# apollo3p register map
Vendor: Ambiq Micro; Series: Apollo; File version: 1.0
CPU: CM4 r1p0, little endian, MPU, FPU, I-cache, D-cache, VTOR, ITCM, DTCM, 3 interrupt priority bits, 0 interrupts
Registers are 32-bit, read-write, reset 0x0 unless marked. A register's access mark holds for its fields unless they carry their own. Offsets are from the block's base; [hi:lo] are bit positions; lines under a group give offsets from that group; {n}, {i} and the like mark numbered series; 'fields as' and 'values as' point back to an identical list.

## GPIO (part 1 of 2) — General Purpose IO
Base 0x40010000
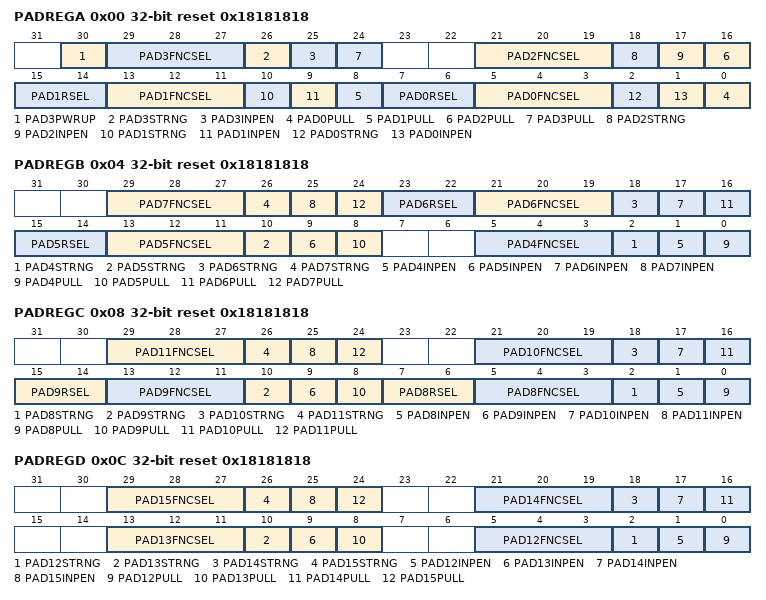
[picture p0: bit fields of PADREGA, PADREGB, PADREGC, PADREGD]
0x00 PADREGA reset 0x18181818 — This register controls the pad configuration controls for PAD3 through PAD0. Writes to this register must be unlocked by the PADKEY register.
  [30] PAD3PWRUP — Pad 3 VDD power switch enable
    0=DIS (Power switch disabled); 1=EN (Power switch enabled (switched to VDD))
  [29:27] PAD3FNCSEL — Pad 3 function select
    0=UA0RTS (Configure as the UART0 RTS output); 1=SLnCE (Configure as the IOSLAVE SPI nCE signal); 2=NCE3 (IOM/MSPI nCE group 3); 3=GPIO3 (Configure as GPIO3); 5=MSPI7 (MSPI data connection 7); 6=TRIG1 (Configure as the ADC Trigger 1 signal); 7=I2S_WCLK (Configure as the PDM I2S Word Clock input)
  [26] PAD3STRNG — Pad 3 drive strength.
    0=LOW (Low drive strength); 1=HIGH (High drive strength)
  [25] PAD3INPEN — Pad 3 input enable.
    0=DIS (Pad input disabled); 1=EN (Pad input enabled)
  [8n] PAD{n}PULL (n=0..3) — Pad {n} pullup enable
    0=DIS (Pullup disabled); 1=EN (Pullup enabled)
  [21:19] PAD2FNCSEL — Pad 2 function select
    0=UART1RX (Configure as the UART1 RX input.); 1=SLMISO (Configure as the IOSLAVE SPI MISO signal.); 2=UART0RX (Configure as the UART0 RX input.); 3=GPIO2 (Configure as GPIO2.); 5=MSPI6 (MSPI data connection 6.); 7=NCE2 (IOM/MSPI nCE group 2)
  [18] PAD2STRNG — Pad 2 drive strength
    0=LOW (Low drive strength); 1=HIGH (High drive strength)
  [17] PAD2INPEN — Pad 2 input enable
    0=DIS (Pad input disabled); 1=EN (Pad input enabled)
  [15:14] PAD1RSEL — Pad 1 pullup resistor selection.
    0=PULL1_5K (Pullup is ~1.5 KOhms); 1=PULL6K (Pullup is ~6 KOhms); 2=PULL12K (Pullup is ~12 KOhms); 3=PULL24K (Pullup is ~24 KOhms)
  [13:11] PAD1FNCSEL — Pad 1 function select
    0=SLSDAWIR3 (Configure as the IOSLAVE I2C SDA or SPI WIR3 signal); 1=SLMOSI (Configure as the IOSLAVE SPI MOSI signal); 2=UART0TX (Configure as the UART0 TX output signal); 3=GPIO1 (Configure as GPIO1); 5=MSPI5 (MSPI data connection 5); 7=NCE1 (IOM/MSPI nCE group 1)
  [10] PAD1STRNG — Pad 1 drive strength
    0=LOW (Low drive strength); 1=HIGH (High drive strength)
  [9] PAD1INPEN — Pad 1 input enable
    0=DIS (Pad input disabled); 1=EN (Pad input enabled)
  [7:6] PAD0RSEL — Pad 0 pullup resistor selection.
    values as PAD1RSEL
  [5:3] PAD0FNCSEL — Pad 0 function select
    0=SLSCL (Configure as the IOSLAVE I2C SCL signal); 1=SLSCK (Configure as the IOSLAVE SPI SCK signal); 2=CLKOUT (Configure as the CLKOUT signal); 3=GPIO0 (Configure as GPIO0); 5=MSPI4 (MSPI data connection 4); 7=NCE0 (IOM/MSPI nCE group 0)
  [2] PAD0STRNG — Pad 0 drive strength
    0=LOW (Low drive strength); 1=HIGH (High drive strength)
  [1] PAD0INPEN — Pad 0 input enable
    0=DIS (Pad input disabled); 1=EN (Pad input enabled)
0x04 PADREGB reset 0x18181818 — This register controls the pad configuration controls for PAD7 through PAD4. Writes to this register must be unlocked by the PADKEY register.
  [29:27] PAD7FNCSEL — Pad 7 function select
    0=NCE7 (IOM/MSPI nCE group 7); 1=M0MOSI (Configure as the IOMSTR0 SPI MOSI signal); 2=CLKOUT (Configure as the CLKOUT signal); 3=GPIO7 (Configure as GPIO7); 4=TRIG0 (Configure as the ADC Trigger 0 signal); 5=UART0TX (Configure as the UART0 TX output signal); 7=CT19 (CTIMER connection 19)
  [8n-30] PAD{n}STRNG (n=4..7) — Pad {n} drive strength
    0=LOW (Low drive strength); 1=HIGH (High drive strength)
  [8n-31] PAD{n}INPEN (n=4..7) — Pad {n} input enable
    0=DIS (Pad input disabled); 1=EN (Pad input enabled)
  [8n-32] PAD{n}PULL (n=4..7) — Pad {n} pullup enable
    0=DIS (Pullup disabled); 1=EN (Pullup enabled)
  [23:22] PAD6RSEL — Pad 6 pullup resistor selection.
    values as PADREGA.PAD1RSEL
  [21:19] PAD6FNCSEL — Pad 6 function select
    0=M0SDAWIR3 (Configure as the IOMSTR0 I2C SDA or SPI WIR3 signal); 1=M0MISO (Configure as the IOMSTR0 SPI MISO signal); 2=UA0CTS (Configure as the UART0 CTS input signal); 3=GPIO6 (Configure as GPIO6); 5=CT10 (CTIMER connection 10); 7=I2S_DAT (Configure as the PDM I2S Data output signal)
  [15:14] PAD5RSEL — Pad 5 pullup resistor selection.
    values as PADREGA.PAD1RSEL
  [13:11] PAD5FNCSEL — Pad 5 function select
    0=M0SCL (Configure as the IOMSTR0 I2C SCL signal); 1=M0SCK (Configure as the IOMSTR0 SPI SCK signal); 2=UA0RTS (Configure as the UART0 RTS signal output); 3=GPIO5 (Configure as GPIO5); 5=EXTHFA (Configure as the External HFA input clock); 7=CT8 (CTIMER connection 8)
  [5:3] PAD4FNCSEL — Pad 4 function select
    0=UA0CTS (Configure as the UART0 CTS input signal); 1=SLINT (Configure as the IOSLAVE interrupt out signal); 2=NCE4 (IOM/SPI nCE group 4); 3=GPIO4 (Configure as GPIO4); 5=UART0RX (Configure as the UART0 RX input); 6=CT17 (CTIMER connection 17); 7=MSPI2 (MSPI data connection 2)
0x08 PADREGC reset 0x18181818 — This register controls the pad configuration controls for PAD11 through PAD8. Writes to this register must be unlocked by the PADKEY register.
  [29:27] PAD11FNCSEL — Pad 11 function select
    0=ADCSE2 (Configure as the analog input for ADC single ended input 2); 1=NCE11 (IOM/MSPI nCE group 11); 2=CT31 (CTIMER connection 31); 3=GPIO11 (Configure as GPIO11); 4=SLINT (Configure as the IOSLAVE interrupt out signal); 5=UA1CTS (Configure as the UART1 CTS input signal); 6=UART0RX (Configure as the UART0 RX input signal); 7=PDM_DATA (Configure as the PDM Data input signal)
  [8n-62] PAD{n}STRNG (n=8..11) — Pad {n} drive strength
    0=LOW (Low drive strength); 1=HIGH (High drive strength)
  [8n-63] PAD{n}INPEN (n=8..11) — Pad {n} input enable
    0=DIS (Pad input disabled); 1=EN (Pad input enabled)
  [8n-64] PAD{n}PULL (n=8..11) — Pad {n} pullup enable
    0=DIS (Pullup disabled); 1=EN (Pullup enabled)
  [21:19] PAD10FNCSEL — Pad 10 function select
    1=M1MOSI (Configure as the IOMSTR1 SPI MOSI signal); 2=NCE10 (IOM/MSPI nCE group 10); 3=GPIO10 (Configure as GPIO10); 4=PDMCLK (PDM serial clock out); 5=UA1RTS (Configure as the UART1 RTS output signal)
  [15:14] PAD9RSEL — Pad 9 pullup resistor selection
    values as PADREGA.PAD1RSEL
  [13:11] PAD9FNCSEL — Pad 9 function select
    0=M1SDAWIR3 (Configure as the IOMSTR1 I2C SDA or SPI WIR3 signal); 1=M1MISO (Configure as the IOMSTR1 SPI MISO signal); 2=NCE9 (IOM/MSPI nCE group 9); 3=GPIO9 (Configure as GPIO9); 4=SCCIO (SCARD data I/O connection); 6=UART1RX (Configure as UART1 RX input signal)
  [7:6] PAD8RSEL — Pad 8 pullup resistor selection.
    values as PADREGA.PAD1RSEL
  [5:3] PAD8FNCSEL — Pad 8 function select
    0=M1SCL (Configure as the IOMSTR1 I2C SCL signal); 1=M1SCK (Configure as the IOMSTR1 SPI SCK signal); 2=NCE8 (IOM/MSPI nCE group 8); 3=GPIO8 (Configure as GPIO8); 4=SCCLK (SCARD serial clock output); 6=UART1TX (Configure as the UART1 TX output signal)
0x0C PADREGD reset 0x18181818 — This register controls the pad configuration controls for PAD15 through PAD12. Writes to this register must be unlocked by the PADKEY register.
  [29:27] PAD15FNCSEL — Pad 15 function select
    0=ADCD1N (Configure as the analog ADC differential pair 1 N input signal); 1=NCE15 (IOM/MSPI nCE group 15); 2=UART1RX (Configure as the UART1 RX signal); 3=GPIO15 (Configure as GPIO15); 4=PDMDATA (PDM serial data input); 5=EXTXT (Configure as the external XTAL oscillator input); 6=SWDIO (Configure as an alternate port for the SWDIO I/O signal); 7=SWO (Configure as an SWO (Serial Wire Trace output))
  [8n-94] PAD{n}STRNG (n=12..15) — Pad {n} drive strength
    0=LOW (Low drive strength); 1=HIGH (High drive strength)
  [8n-95] PAD{n}INPEN (n=12..15) — Pad {n} input enable
    0=DIS (Pad input disabled); 1=EN (Pad input enabled)
  [8n-96] PAD{n}PULL (n=12..15) — Pad {n} pullup enable
    0=DIS (Pullup disabled); 1=EN (Pullup enabled)
  [21:19] PAD14FNCSEL — Pad 14 function select
    0=ADCD1P (Configure as the analog ADC differential pair 1 P input signal); 1=NCE14 (IOM/MSPI nCE group 14); 2=UART1TX (Configure as the UART1 TX output signal); 3=GPIO14 (Configure as GPIO14); 4=PDMCLK (PDM serial clock output); 5=EXTHFS (Configure as the External HFRC oscillator input select); 6=SWDCK (Configure as the alternate input for the SWDCK input signal); 7=32kHzXT (Configure as the 32kHz crystal output signal)
  [13:11] PAD13FNCSEL — Pad 13 function select
    0=ADCD0PSE8 (Configure as the ADC Differential pair 0 P, or Single Ended input 8 analog input signal. Determination of the D0P vs SE8 usage is done when the particular channel is selected within the ADC module); 1=NCE13 (IOM/MSPI nCE group 13); 2=CT2 (CTIMER connection 2); 3=GPIO13 (Configure as GPIO13); 4=I2SBCLK (I2C interface bit clock); 5=EXTHFB (Configure as the external HFRC oscillator input); 6=UA0RTS (Configure as the UART0 RTS signal output); 7=UART1RX (Configure as the UART1 RX input signal)
  [5:3] PAD12FNCSEL — Pad 12 function select
    0=ADCD0NSE9 (Configure as the ADC Differential pair 0 N, or Single Ended input 9 analog input signal. Determination of the D0N vs SE9 usage is done when the particular channel is selected within the ADC module); 1=NCE12 (IOM/MSPI nCE group 12); 2=CT0 (CTIMER connection 0); 3=GPIO12 (Configure as GPIO12); 5=PDMCLK (PDM serial clock output); 6=UA0CTS (Configure as the UART0 CTS input signal); 7=UART1TX (Configure as the UART1 TX output signal)
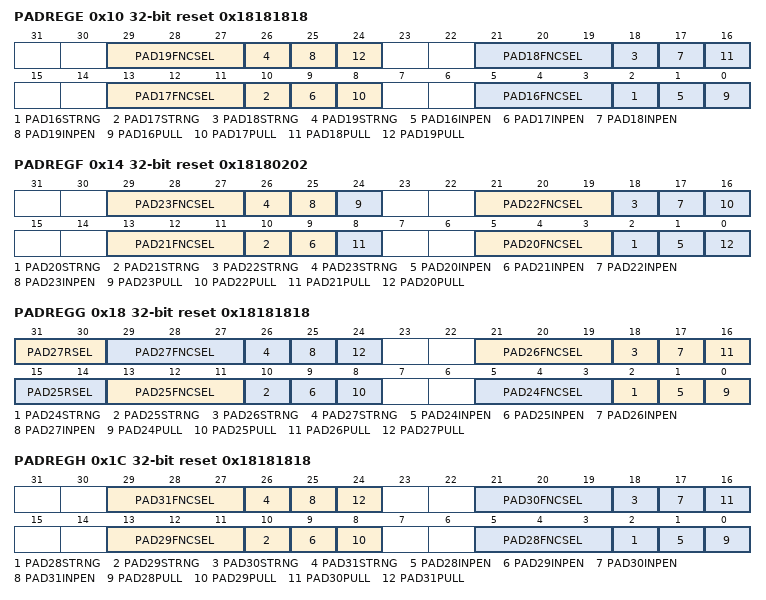
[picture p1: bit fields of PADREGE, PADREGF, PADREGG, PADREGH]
0x10 PADREGE reset 0x18181818 — This register controls the pad configuration controls for PAD19 through PAD16. Writes to this register must be unlocked by the PADKEY register.
  [29:27] PAD19FNCSEL — Pad 19 function select
    0=CMPRF0 (Configure as the analog comparator reference 0 signal); 1=NCE19 (IOM/MSPI nCE group 19); 2=CT6 (CTIMER connection 6); 3=GPIO19 (Configure as GPIO19); 4=SCCLK (SCARD serial clock); 5=ANATEST1 (Configure as the ANATEST1 I/O signal); 6=UART1RX (Configure as the UART1 RX input signal); 7=I2SBCLK (Configure as the PDM I2S bit clock input signal)
  [8n-126] PAD{n}STRNG (n=16..19) — Pad {n} drive strength
    0=LOW (Low drive strength); 1=HIGH (High drive strength)
  [8n-127] PAD{n}INPEN (n=16..19) — Pad {n} input enable
    0=DIS (Pad input disabled); 1=EN (Pad input enabled)
  [8n-128] PAD{n}PULL (n=16..19) — Pad {n} pullup enable
    0=DIS (Pullup disabled); 1=EN (Pullup enabled)
  [21:19] PAD18FNCSEL — Pad 18 function select
    0=CMPIN1 (Configure as the analog comparator input 1 signal); 1=NCE18 (IOM/MSPI nCE group 18); 2=CT4 (CTIMER connection 4); 3=GPIO18 (Configure as GPIO18); 4=UA0RTS (Configure as UART0 RTS output signal); 5=ANATEST2 (Configure as ANATEST2 I/O signal); 6=UART1TX (Configure as UART1 TX output signal); 7=SCCIO (SCARD data input/output connection)
  [13:11] PAD17FNCSEL — Pad 17 function select
    0=CMPRF1 (Configure as the analog comparator reference signal 1 input signal); 1=NCE17 (IOM/MSPI nCE group 17); 2=TRIG1 (Configure as the ADC Trigger 1 signal); 3=GPIO17 (Configure as GPIO17); 4=SCCCLK (SCARD serial clock output); 6=UART0RX (Configure as UART0 RX input signal); 7=UA1CTS (Configure as UART1 CTS input signal)
  [5:3] PAD16FNCSEL — Pad 16 function select
    0=ADCSE0 (Configure as the analog ADC single ended port 0 input signal); 1=NCE16 (IOM/MSPI nCE group 16); 2=TRIG0 (Configure as the ADC Trigger 0 signal); 3=GPIO16 (Configure as GPIO16); 4=SCCRST (SCARD reset output); 5=CMPIN0 (Configure as comparator input 0 signal); 6=UART0TX (Configure as UART0 TX output signal); 7=UA1RTS (Configure as UART1 RTS output signal)
0x14 PADREGF reset 0x18180202 — This register controls the pad configuration controls for PAD23 through PAD20. Writes to this register must be unlocked by the PADKEY register.
  [29:27] PAD23FNCSEL — Pad 23 function select
    0=UART0RX (Configure as the UART0 RX signal); 1=NCE23 (IOM/MSPI nCE group 23); 2=CT14 (CTIMER connection 14); 3=GPIO23 (Configure as GPIO23); 4=I2SWCLK (I2S word clock input); 5=CMPOUT (Configure as voltage comparator output); 6=MSPI3 (MSPI data connection 3); 7=EXTXT (External XTAL oscillator input)
  [8n-158] PAD{n}STRNG (n=20..23) — Pad {n} drive strength
    0=LOW (Low drive strength); 1=HIGH (High drive strength)
  [8n-159] PAD{n}INPEN (n=20..23) — Pad {n} input enable
    0=DIS (Pad input disabled); 1=EN (Pad input enabled)
  [24] PAD23PULL — Pad 23 pullup enable
    0=DIS (Pullup disabled); 1=EN (Pullup enabled)
  [21:19] PAD22FNCSEL — Pad 22 function select
    0=UART0TX (Configure as the UART0 TX signal); 1=NCE22 (IOM/MSPI nCE group 22); 2=CT12 (CTIMER connection 12); 3=GPIO22 (Configure as GPIO22); 4=PDM_CLK (Configure as the PDM CLK output); 5=EXTLF (External LFRC input); 6=MSPI0 (MSPI data connection 0); 7=SWO (Configure as the serial trace data output signal)
  [16] PAD22PULL — Pad 22 pullup enable
    0=DIS (Pullup disabled); 1=EN (Pullup enabled)
  [13:11] PAD21FNCSEL — Pad 21 function select
    0=SWDIO (Configure as the serial wire debug data signal); 1=NCE21 (IOM/MSPI nCE group 21); 3=GPIO21 (Configure as GPIO21); 4=UART0RX (Configure as UART0 RX input signal); 5=UART1RX (Configure as UART1 RX input signal); 6=I2SBCLK (I2S byte clock input); 7=UA1CTS (Configure as UART1 CTS input signal)
  [8] PAD21PULL — Pad 21 pullup enable
    0=DIS (Pullup disabled); 1=EN (Pullup enabled)
  [5:3] PAD20FNCSEL — Pad 20 function select
    0=SWDCK (Configure as the serial wire debug clock signal); 1=NCE20 (IOM/MSPI nCE group 20); 3=GPIO20 (Configure as GPIO20); 4=UART0TX (Configure as UART0 TX output signal); 5=UART1TX (Configure as UART1 TX output signal); 6=I2SBCLK (I2S byte clock input); 7=UA1RTS (Configure as UART1 RTS output signal)
  [0] PAD20PULL — Pad 20 pulldown enable
    0=DIS (Pulldown disabled); 1=EN (Pulldown enabled)
0x18 PADREGG reset 0x18181818 — This register controls the pad configuration controls for PAD27 through PAD24. Writes to this register must be unlocked by the PADKEY register.
  [31:30] PAD27RSEL — Pad 27 pullup resistor selection.
    values as PADREGA.PAD1RSEL
  [29:27] PAD27FNCSEL — Pad 27 function select
    0=UART0RX (Configure as UART0 RX input signal); 1=NCE27 (IOM/MSPI nCE group 27); 2=CT5 (CTIMER connection 5); 3=GPIO27 (Configure as GPIO27); 4=M2SCL (Configure as I2C clock I/O signal from IOMSTR2); 5=M2SCK (Configure as SPI clock output signal from IOMSTR2)
  [8n-190] PAD{n}STRNG (n=24..27) — Pad {n} drive strength
    0=LOW (Low drive strength); 1=HIGH (High drive strength)
  [8n-191] PAD{n}INPEN (n=24..27) — Pad {n} input enable
    0=DIS (Pad input disabled); 1=EN (Pad input enabled)
  [8n-192] PAD{n}PULL (n=24..27) — Pad {n} pullup enable
    0=DIS (Pullup disabled); 1=EN (Pullup enabled)
  [21:19] PAD26FNCSEL — Pad 26 function select
    0=EXTHF (Configure as the external HFRC oscillator input); 1=NCE26 (IOM/MSPI nCE group 26); 2=CT3 (CTIMER connection 3); 3=GPIO26 (Configure as GPIO26); 4=SCCRST (SCARD reset output); 5=MSPI1 (MSPI data connection 1); 6=UART0TX (Configure as UART0 TX output signal); 7=UA1CTS (Configure as UART1 CTS input signal)
  [15:14] PAD25RSEL — Pad 25 pullup resistor selection.
    values as PADREGA.PAD1RSEL
  [13:11] PAD25FNCSEL — Pad 25 function select
    0=UART1RX (Configure as UART1 RX input signal); 1=NCE25 (IOM/MSPI nCE group 25); 2=CT1 (CTIMER connection 1); 3=GPIO25 (Configure as GPIO25); 4=M2SDAWIR3 (Configure as the IOMSTR2 I2C SDA or SPI WIR3 signal); 5=M2MISO (Configure as the IOMSTR2 SPI MISO input signal)
  [5:3] PAD24FNCSEL — Pad 24 function select
    0=UART1TX (Configure as UART1 TX output signal); 1=NCE24 (IOM/MSPI nCE group 24); 2=MSPI8 (MSPI data connection 8); 3=GPIO24 (Configure as GPIO24); 4=UA0CTS (Configure as UART0 CTS input signal); 5=CT21 (CTIMER connection 21); 6=32kHzXT (Configure as the 32kHz crystal output signal); 7=SWO (Configure as the serial trace data output signal)
0x1C PADREGH reset 0x18181818 — This register controls the pad configuration controls for PAD31 through PAD28. Writes to this register must be unlocked by the PADKEY register.
  [29:27] PAD31FNCSEL — Pad 31 function select
    0=ADCSE3 (Configure as the analog input for ADC single ended input 3); 1=NCE31 (IOM/MSPI nCE group 31); 2=CT13 (CTIMER connection 13); 3=GPIO31 (Configure as GPIO31); 4=UART0RX (Configure as the UART0 RX input signal); 5=SCCCLK (SCARD serial clock output); 7=UA1RTS (Configure as UART1 RTS output signal)
  [8n-222] PAD{n}STRNG (n=28..31) — Pad {n} drive strength
    0=LOW (Low drive strength); 1=HIGH (High drive strength)
  [8n-223] PAD{n}INPEN (n=28..31) — Pad {n} input enable
    0=DIS (Pad input disabled); 1=EN (Pad input enabled)
  [8n-224] PAD{n}PULL (n=28..31) — Pad {n} pullup enable
    0=DIS (Pullup disabled); 1=EN (Pullup enabled)
  [21:19] PAD30FNCSEL — Pad 30 function select
    0=ANATEST1 (Configure as the ANATEST1 I/O signal); 1=NCE30 (IOM/MSPI nCE group 30); 2=CT11 (CTIMER connection 11); 3=GPIO30 (Configure as GPIO30); 4=UART0TX (Configure as UART0 TX output signal); 5=UA1RTS (Configure as UART1 RTS output signal); 7=I2S_DAT (Configure as the PDM I2S Data output signal)
  [13:11] PAD29FNCSEL — Pad 29 function select
    0=ADCSE1 (Configure as the analog input for ADC single ended input 1); 1=NCE29 (IOM/MSPI nCE group 29); 2=CT9 (CTIMER connection 9); 3=GPIO29 (Configure as GPIO29); 4=UA0CTS (Configure as the UART0 CTS input signal); 5=UA1CTS (Configure as the UART1 CTS input signal); 6=UART0RX (Configure as the UART0 RX input signal); 7=PDM_DATA (Configure as PDM DATA input)
  [5:3] PAD28FNCSEL — Pad 28 function select
    0=I2S_WCLK (Configure as the PDM I2S Word Clock input); 1=NCE28 (IOM/MSPI nCE group 28); 2=CT7 (CTIMER connection 7); 3=GPIO28 (Configure as GPIO28); 5=M2MOSI (Configure as the IOMSTR2 SPI MOSI output signal); 6=UART0TX (Configure as the UART0 TX output signal)
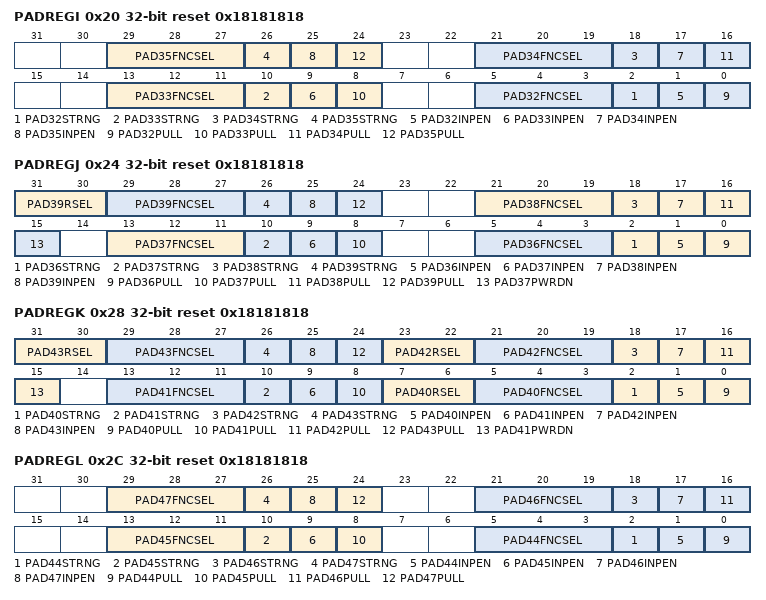
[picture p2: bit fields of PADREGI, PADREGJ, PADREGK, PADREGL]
0x20 PADREGI reset 0x18181818 — This register controls the pad configuration controls for PAD35 through PAD32. Writes to this register must be unlocked by the PADKEY register.
  [29:27] PAD35FNCSEL — Pad 35 function select
    0=ADCSE7 (Configure as the analog input for ADC single ended input 7); 1=NCE35 (IOM/MSPI nCE group 35); 2=UART1TX (Configure as the UART1 TX signal); 3=GPIO35 (Configure as GPIO35); 4=I2SDAT (I2S serial data output); 5=CT27 (CTIMER connection 27); 6=UA0RTS (Configure as the UART0 RTS output)
  [8n-254] PAD{n}STRNG (n=32..35) — Pad {n} drive strength
    0=LOW (Low drive strength); 1=HIGH (High drive strength)
  [8n-255] PAD{n}INPEN (n=32..35) — Pad {n} input enable
    0=DIS (Pad input disabled); 1=EN (Pad input enabled)
  [8n-256] PAD{n}PULL (n=32..35) — Pad {n} pullup enable
    0=DIS (Pullup disabled); 1=EN (Pullup enabled)
  [21:19] PAD34FNCSEL — Pad 34 function select
    0=ADCSE6 (Configure as the analog input for ADC single ended input 6); 1=NCE34 (IOM/MSPI nCE group 34); 2=UA1RTS (Configure as the UART1 RTS output); 3=GPIO34 (Configure as GPIO34); 4=CMPRF2 (Configure as the analog comparator reference 2 signal); 5=UA0RTS (Configure as the UART0 RTS output); 6=UART0RX (Configure as the UART0 RX input); 7=PDMDATA (PDM serial data input)
  [13:11] PAD33FNCSEL — Pad 33 function select
    0=ADCSE5 (Configure as the analog ADC single ended port 5 input signal); 1=NCE33 (IOM/MSPI nCE group 33); 2=32kHzXT (Configure as the 32kHz crystal output signal); 3=GPIO33 (Configure as GPIO33); 5=UA0CTS (Configure as the UART0 CTS input); 6=CT23 (CTIMER connection 23); 7=SWO (Configure as the serial trace data output signal)
  [5:3] PAD32FNCSEL — Pad 32 function select
    0=ADCSE4 (Configure as the analog input for ADC single ended input 4); 1=NCE32 (IOM/MSPI nCE group 32); 2=CT15 (CTIMER connection 15); 3=GPIO32 (Configure as GPIO32); 4=SCCIO (SCARD serial data input/output); 5=EXTLF (External input to the LFRC oscillator); 7=UA1CTS (Configure as the UART1 CTS input)
0x24 PADREGJ reset 0x18181818 — This register controls the pad configuration controls for PAD39 through PAD36. Writes to this register must be unlocked by the PADKEY register.
  [31:30] PAD39RSEL — Pad 39 pullup resistor selection.
    values as PADREGA.PAD1RSEL
  [29:27] PAD39FNCSEL — Pad 39 function select
    0=UART0TX (Configure as the UART0 TX output signal); 1=UART1TX (Configure as the UART1 TX output signal); 2=CT25 (CTIMER connection 25); 3=GPIO39 (Configure as GPIO39); 4=M4SCL (Configure as the IOMSTR4 I2C SCL signal); 5=M4SCK (Configure as the IOMSTR4 SPI SCK signal)
  [8n-286] PAD{n}STRNG (n=36..39) — Pad {n} drive strength
    0=LOW (Low drive strength); 1=HIGH (High drive strength)
  [8n-287] PAD{n}INPEN (n=36..39) — Pad {n} input enable
    0=DIS (Pad input disabled); 1=EN (Pad input enabled)
  [8n-288] PAD{n}PULL (n=36..39) — Pad {n} pullup enable
    0=DIS (Pullup disabled); 1=EN (Pullup enabled)
  [21:19] PAD38FNCSEL — Pad 38 function select
    0=TRIG3 (Configure as the ADC Trigger 3 signal); 1=NCE38 (IOM/MSPI nCE group 38); 2=UA0CTS (Configure as the UART0 CTS signal); 3=GPIO38 (Configure as GPIO38); 5=M3MOSI (Configure as the IOMSTR3 SPI MOSI output signal); 6=UART1RX (Configure as the UART1 RX input signal)
  [15] PAD37PWRDN — Pad 37 VSS power switch enable
    0=DIS (Power switch disabled); 1=EN (Power switch enabled (switch to GND))
  [13:11] PAD37FNCSEL — Pad 37 function select
    0=TRIG2 (Configure as the ADC Trigger 2 signal); 1=NCE37 (IOM/MSPI nCE group 37); 2=UA0RTS (Configure as the UART0 RTS output signal); 3=GPIO37 (Configure as GPIO37); 4=SCCIO (SCARD serial data input/output); 5=UART1TX (Configure as the UART1 TX output signal); 6=PDMCLK (Configure as the PDM CLK output signal); 7=CT29 (CTIMER connection 29)
  [5:3] PAD36FNCSEL — Pad 36 function select
    0=TRIG1 (Configure as the ADC Trigger 1 signal); 1=NCE36 (IOM/MSPI nCE group 36); 2=UART1RX (Configure as the UART1 RX input signal); 3=GPIO36 (Configure as GPIO36); 4=32kHzXT (Configure as the 32kHz output clock from the crystal); 5=UA1CTS (Configure as the UART1 CTS input signal); 6=UA0CTS (Configure as the UART0 CTS input signal); 7=PDMDATA (PDM serial data input)
0x28 PADREGK reset 0x18181818 — This register controls the pad configuration controls for PAD43 through PAD40. Writes to this register must be unlocked by the PADKEY register.
  [31:30] PAD43RSEL — Pad 43 pullup resistor selection.
    values as PADREGA.PAD1RSEL
  [29:27] PAD43FNCSEL — Pad 43 function select
    0=UART1RX (Configure as the UART1 RX input signal); 1=NCE43 (IOM/MSPI nCE group 43); 2=CT18 (CTIMER connection 18); 3=GPIO43 (Configure as GPIO43); 4=M3SDAWIR3 (Configure as the IOMSTR3 I2C SDA or SPI WIR3 signal); 5=M3MISO (Configure as the IOMSTR3 SPI MISO signal)
  [8n-318] PAD{n}STRNG (n=40..43) — Pad {n} drive strength
    0=LOW (Low drive strength); 1=HIGH (High drive strength)
  [8n-319] PAD{n}INPEN (n=40..43) — Pad {n} input enable
    0=DIS (Pad input disabled); 1=EN (Pad input enabled)
  [8n-320] PAD{n}PULL (n=40..43) — Pad {n} pullup enable
    0=DIS (Pullup disabled); 1=EN (Pullup enabled)
  [23:22] PAD42RSEL — Pad 42 pullup resistor selection.
    values as PADREGA.PAD1RSEL
  [21:19] PAD42FNCSEL — Pad 42 function select
    0=UART1TX (Configure as the UART1 TX output signal); 1=NCE42 (IOM/MSPI nCE group 42); 2=CT16 (CTIMER connection 16); 3=GPIO42 (Configure as GPIO42); 4=M3SCL (Configure as the IOMSTR3 I2C SCL clock I/O signal); 5=M3SCK (Configure as the IOMSTR3 SPI SCK output)
  [15] PAD41PWRDN — Pad 41 power switch enable
    0=DIS (Power switch disabled); 1=EN (Power switch enabled (Switch pad to VSS))
  [13:11] PAD41FNCSEL — Pad 41 function select
    0=NCE41 (IOM/MSPI nCE group 41); 2=SWO (Configure as the serial wire debug SWO signal); 3=GPIO41 (Configure as GPIO41); 4=I2SWCLK (I2S word clock input); 5=UA1RTS (Configure as the UART1 RTS output signal); 6=UART0TX (Configure as the UART0 TX output signal); 7=UA0RTS (Configure as the UART0 RTS output signal)
  [7:6] PAD40RSEL — Pad 40 pullup resistor selection.
    values as PADREGA.PAD1RSEL
  [5:3] PAD40FNCSEL — Pad 40 function select
    0=UART0RX (Configure as the UART0 RX input signal); 1=UART1RX (Configure as the UART1 RX input signal); 2=TRIG0 (Configure as the ADC Trigger 0 signal); 3=GPIO40 (Configure as GPIO40); 4=M4SDAWIR3 (Configure as the IOMSTR4 I2C SDA or SPI WIR3 signal); 5=M4MISO (Configure as the IOMSTR4 SPI MISO input signal)
0x2C PADREGL reset 0x18181818 — This register controls the pad configuration controls for PAD47 through PAD44. Writes to this register must be unlocked by the PADKEY register.
  [29:27] PAD47FNCSEL — Pad 47 function select
    0=32kHzXT (Configure as the 32kHz output clock from the crystal); 1=NCE47 (IOM/MSPI nCE group 47); 2=CT26 (CTIMER connection 26); 3=GPIO47 (Configure as GPIO47); 5=M5MOSI (Configure as the IOMSTR5 SPI MOSI output signal); 6=UART1RX (Configure as the UART1 RX input signal)
  [8n-350] PAD{n}STRNG (n=44..47) — Pad {n} drive strength
    0=LOW (Low drive strength); 1=HIGH (High drive strength)
  [8n-351] PAD{n}INPEN (n=44..47) — Pad {n} input enable
    0=DIS (Pad input disabled); 1=EN (Pad input enabled)
  [8n-352] PAD{n}PULL (n=44..47) — Pad {n} pullup enable
    0=DIS (Pullup disabled); 1=EN (Pullup enabled)
  [21:19] PAD46FNCSEL — Pad 46 function select
    0=32khz_XT (Configure as the 32kHz output clock from the crystal); 1=NCE46 (IOM/MSPI nCE group 46); 2=CT24 (CTIMER connection 24); 3=GPIO46 (Configure as GPIO46); 4=SCCRST (SCARD reset output); 5=PDMCLK (PDM serial clock output); 6=UART1TX (Configure as the UART1 TX output signal); 7=SWO (Configure as the serial wire debug SWO signal)
  [13:11] PAD45FNCSEL — Pad 45 function select
    0=UA1CTS (Configure as the UART1 CTS input signal); 1=NCE45 (IOM/MSPI nCE group 45); 2=CT22 (CTIMER connection 22); 3=GPIO45 (Configure as GPIO45); 4=I2SDAT (I2S serial data output); 5=PDMDATA (PDM serial data input); 6=UART0RX (Configure as the SPI channel 5 nCE signal from IOMSTR5); 7=SWO (Configure as the serial wire debug SWO signal)
  [5:3] PAD44FNCSEL — Pad 44 function select
    0=UA1RTS (Configure as the UART1 RTS output signal); 1=NCE44 (IOM/MSPI nCE group 44); 2=CT20 (CTIMER connection 20); 3=GPIO44 (Configure as GPIO44); 5=M4MOSI (Configure as the IOMSTR4 SPI MOSI signal); 6=M5nCE6 (Configure as the SPI channel 6 nCE signal from IOMSTR5)
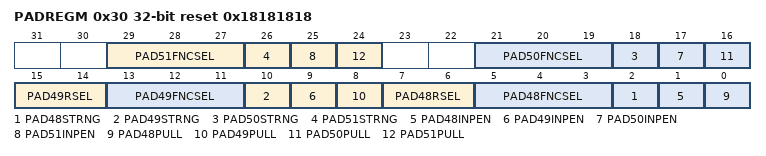
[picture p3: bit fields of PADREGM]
0x30 PADREGM reset 0x18181818 — This register controls the pad configuration controls for PAD48 through PAD51. Writes to this register must be unlocked by the PADKEY register.
  [29:27] PAD51FNCSEL — Pad 51 function select
    0=MSPI1_0 (Configure as the MSPI1 0 signal); 1=NCE51 (IOM/MSPI nCE group 51); 2=CT1 (CTIMER connection 1); 3=GPIO51 (Configure as GPIO51)
  [8n-382] PAD{n}STRNG (n=48..51) — Pad {n} drive strength
    0=LOW (Low drive strength); 1=HIGH (High drive strength)
  [8n-383] PAD{n}INPEN (n=48..51) — Pad {n} input enable
    0=DIS (Pad input disabled); 1=EN (Pad input enabled)
  [8n-384] PAD{n}PULL (n=48..51) — Pad {n} pullup enable
    0=DIS (Pullup disabled); 1=EN (Pullup enabled)
  [21:19] PAD50FNCSEL — Pad 50 function select
    0=SWO (Configure as the SWO output); 1=NCE50 (IOM/MSPI nCE group 50); 2=CT0 (CTIMER connection 0); 3=GPIO50 (Configure as GPIO50); 4=UART0TX (Configure as the UART0 TX output); 5=UART0RX (Configure as the UART0 RX input); 6=UART1TX (Configure as the UART1 TX output); 7=UART1RX (Configure as the UART1 RX input)
  [15:14] PAD49RSEL — Pad 49 pullup resistor selection.
    values as PADREGA.PAD1RSEL
  [13:11] PAD49FNCSEL — Pad 49 function select
    0=UART0RX (Configure as the UART0 RX input signal); 1=NCE49 (IOM/MSPPI nCE group 49); 2=CT30 (CTIMER connection 30); 3=GPIO49 (Configure as GPIO49); 4=M5SDAWIR3 (Configure as the IOMSTR5 I2C SDA or SPI WIR3 signal); 5=M5MISO (Configure as the IOMSTR5 SPI MISO input signal)
  [7:6] PAD48RSEL — Pad 48 pullup resistor selection.
    values as PADREGA.PAD1RSEL
  [5:3] PAD48FNCSEL — Pad 48 function select
    0=UART0TX (Configure as the UART0 TX output signal); 1=NCE48 (IOM/MSPI nCE group 48); 2=CT28 (CTIMER connection 28); 3=GPIO48 (Configure as GPIO48); 4=M5SCL (Configure as the IOMSTR5 I2C SCL clock I/O signal); 5=M5SCK (Configure as the IOMSTR5 SPI SCK output)
